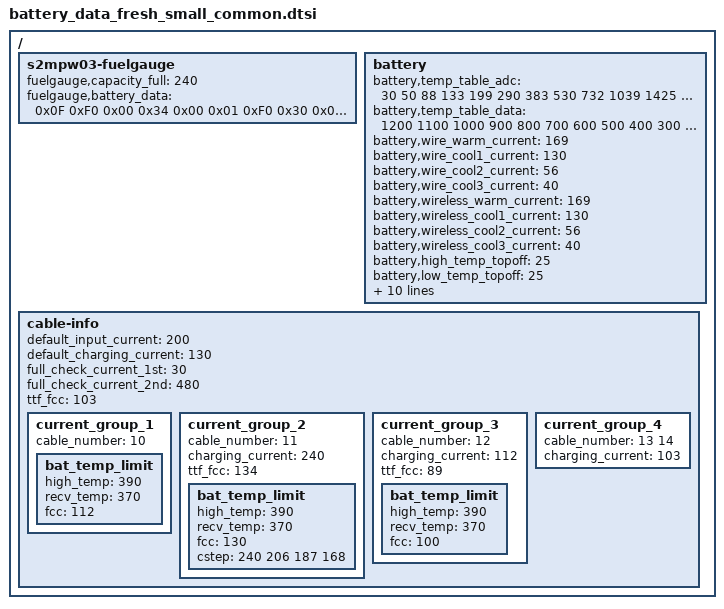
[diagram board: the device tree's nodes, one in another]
/*
 * SAMSUNG EXYNOS5515 board device tree source
 *
 * Copyright (c) 2021 Samsung Electronics Co., Ltd.
 *		http://www.samsung.com
 *
 * This program is free software; you can redistribute it and/or modify
 * it under the terms of the GNU General Public License version 2 as
 * published by the Free Software Foundation.
 */

#include "battery_data_fresh_common.dtsi"

/ {
	fragment@battery {
		target-path = "/";
		__overlay__ {
			s2mpw03-fuelgauge {
				fuelgauge,capacity_full = <240>;

				fuelgauge,battery_data = /bits/ 8 <
					/* 4.42V */
					/* table1 */
					0x0F 0xF0 0x00 0x34 0x00
					/* table2 */
					0x01 0xF0
					/* model_param1 */
					0x30 0x0B 0xD6 0x0A 0x7C 0x0A 0x31 0x0A 0xBB 0x09
					0x48 0x09 0xDA 0x08 0x73 0x08 0x13 0x08 0xA7 0x07
					0x44 0x07 0xFE 0x06 0xC9 0x06 0x9D 0x06 0x78 0x06
					0x54 0x06 0x25 0x06 0xF6 0x05 0xBC 0x05 0x94 0x05
					0x23 0x05 0xCB 0x02 0x66 0x08 0x00 0x08 0x9A 0x07
					0x33 0x07 0xCD 0x06 0x66 0x06 0x00 0x06 0x9A 0x05
					0x33 0x05 0xCD 0x04 0x66 0x04 0x00 0x04 0x9A 0x03
					0x33 0x03 0xCD 0x02 0x66 0x02 0x00 0x02 0x9A 0x01
					0x33 0x01 0xCD 0x00 0x66 0x00 0x00 0x00
					/* model_param2 */
					0xE5 0xFF 0xFF 0xED 0xED 0xE9 0xE4 0xE1 0xDC 0xD9
					0xD7 0xD5 0xDA 0xDC 0xFF 0xFF 0xFF 0xFF 0xF1 0xFE
					0xEA 0xE3

					/* 4.4V */
					/* table1 */
					0x0F 0xE9 0x00 0x34 0x00
					/* table2 */
					0x01 0xF0
					/* model_param1 */
					0x3C 0x0B 0xD0 0x0A 0x64 0x0A 0x1B 0x0A 0xA6 0x09
					0x34 0x09 0xC7 0x08 0x62 0x08 0x04 0x08 0x95 0x07
					0x35 0x07 0xF5 0x06 0xC2 0x06 0x97 0x06 0x73 0x06
					0x4F 0x06 0x1F 0x06 0xF0 0x05 0xB5 0x05 0x92 0x05
					0x0F 0x05 0xCC 0x02 0x66 0x08 0x00 0x08 0x9A 0x07
					0x33 0x07 0xCD 0x06 0x66 0x06 0x00 0x06 0x9A 0x05
					0x33 0x05 0xCD 0x04 0x66 0x04 0x00 0x04 0x9A 0x03
					0x33 0x03 0xCD 0x02 0x66 0x02 0x00 0x02 0x9A 0x01
					0x33 0x01 0xCD 0x00 0x66 0x00 0x00 0x00
					/* model_param2 */
					0xE5 0xFF 0xFF 0xED 0xED 0xE9 0xE4 0xE1 0xDC 0xD9
					0xD7 0xD5 0xDA 0xDC 0xFF 0xFF 0xFF 0xFF 0xF1 0xFE
					0xEA 0xE3

					/* 4.38V */
					/* table1 */
					0x0F 0xE5 0x00 0x34 0x00
					/* table2 */
					0x01 0xF0
					/* model_param1 */
					0x13 0x0B 0xA7 0x0A 0x3B 0x0A 0xF3 0x09 0x81 0x09
					0x13 0x09 0xAA 0x08 0x49 0x08 0xE8 0x07 0x7F 0x07
					0x26 0x07 0xEA 0x06 0xBA 0x06 0x91 0x06 0x6F 0x06
					0x4B 0x06 0x1A 0x06 0xED 0x05 0xB1 0x05 0x91 0x05
					0x0C 0x05 0xCD 0x02 0x66 0x08 0x00 0x08 0x9A 0x07
					0x33 0x07 0xCD 0x06 0x66 0x06 0x00 0x06 0x9A 0x05
					0x33 0x05 0xCD 0x04 0x66 0x04 0x00 0x04 0x9A 0x03
					0x33 0x03 0xCD 0x02 0x66 0x02 0x00 0x02 0x9A 0x01
					0x33 0x01 0xCD 0x00 0x66 0x00 0x00 0x00
					/* model_param2 */
					0xE5 0xFF 0xFF 0xED 0xED 0xE9 0xE4 0xE1 0xDC 0xD9
					0xD7 0xD5 0xDA 0xDC 0xFF 0xFF 0xFF 0xFF 0xF1 0xFE
					0xEA 0xE3

					/* 4.36V */
					/* table1 */
					0x0F 0xE0 0x00 0x34 0x00
					/* table2 */
					0x01 0xF0
					/* model_param1 */
					0xE6 0x0B 0x79 0x0A 0x0C 0x0A 0xC5 0x09 0x56 0x09
					0xED 0x08 0x89 0x08 0x2C 0x08 0xC9 0x07 0x66 0x07
					0x17 0x07 0xDF 0x06 0xB2 0x06 0x8B 0x06 0x69 0x06
					0x45 0x06 0x14 0x06 0xE9 0x05 0xAD 0x05 0x90 0x05
					0x08 0x05 0xCD 0x02 0x66 0x08 0x00 0x08 0x9A 0x07
					0x33 0x07 0xCD 0x06 0x66 0x06 0x00 0x06 0x9A 0x05
					0x33 0x05 0xCD 0x04 0x66 0x04 0x00 0x04 0x9A 0x03
					0x33 0x03 0xCD 0x02 0x66 0x02 0x00 0x02 0x9A 0x01
					0x33 0x01 0xCD 0x00 0x66 0x00 0x00 0x00
					/* model_param2 */
					0xE5 0xFF 0xFF 0xED 0xED 0xE9 0xE4 0xE1 0xDC 0xD9
					0xD7 0xD5 0xDA 0xDC 0xFF 0xFF 0xFF 0xFF 0xF1 0xFE
					0xEA 0xE3

					/* 4.31V */
					/* table1 */
					0x0F 0xD5 0x00 0x34 0x00
					/* table2 */
					0x01 0xF0
					/* model_param1 */
					0x7E 0x0A 0x14 0x0A 0xA9 0x09 0x69 0x09 0x03 0x09
					0xA3 0x08 0x48 0x08 0xEE 0x07 0x8A 0x07 0x33 0x07
					0xF9 0x06 0xC9 0x06 0xA1 0x06 0x7F 0x06 0x5E 0x06
					0x38 0x06 0x0A 0x06 0xE0 0x05 0xA4 0x05 0x8E 0x05
					0x00 0x05 0xCD 0x02 0x66 0x08 0x00 0x08 0x9A 0x07
					0x33 0x07 0xCD 0x06 0x66 0x06 0x00 0x06 0x9A 0x05
					0x33 0x05 0xCD 0x04 0x66 0x04 0x00 0x04 0x9A 0x03
					0x33 0x03 0xCD 0x02 0x66 0x02 0x00 0x02 0x9A 0x01
					0x33 0x01 0xCD 0x00 0x66 0x00 0x00 0x00
					/* model_param2 */
					0xE5 0xFF 0xFF 0xED 0xED 0xE9 0xE4 0xE1 0xDC 0xD9
					0xD7 0xD5 0xDA 0xDC 0xFF 0xFF 0xFF 0xFF 0xF1 0xFE
					0xEA 0xE3
				>;
			};

			battery {
				battery,temp_table_adc = <
							30 50 88 133 199 290 383 530 732 1039
							1425 1871 2365 2853 3324
							>;
				battery,temp_table_data = <
							1200 1100 1000 900 800 700 600 500 400 300
							200 100 0 (-100) (-200)
							>;

				battery,wire_warm_current = <169>;	/* 0.36C */
				battery,wire_cool1_current = <130>;	/* Not used */
				battery,wire_cool2_current = <56>;	/* 0.24C */
				battery,wire_cool3_current = <40>;	/* 0.16C */

				battery,wireless_warm_current = <169>;	/* 0.24C */
				battery,wireless_cool1_current = <130>;	/* Not used */
				battery,wireless_cool2_current = <56>;	/* 0.24C */
				battery,wireless_cool3_current = <40>;	/* 0.16C */

				battery,high_temp_topoff = <25>;	/* 0.05C */
				battery,low_temp_topoff = <25>;		/* 0.05C */

				battery,standard_curr = <169>;
				battery,cc2_charge_current = <169>;
				battery,tct_low_current = <103>;
				battery,store_wpc_current = <75>;
				battery,age_data_cc_cv_threshold = <4150 4150 4150 4150 4150>;

				battery,battery_full_capacity = <240>;
				battery,ttf_capacity = <240>;
				battery,cv_data = <
					182	860	1147
					172	870	1086
					160	880	1026
					146	890	966
					135	900	905
					127	910	845
					118	920	785
					113	930	725
					101	940	604
					96	950	544
					86	960	422
					83	970	362
					74	980	241
					67	990	121
					59	1000	0
					>;
			};

			/* sec_battery_cable
			 *   0	UNKNOWN,
			 *   1	NONE,
			 *   2	TA,
			 *   3	USB,
			 *   4	UARTOFF,
			 *   5	RESERVED,
			 *   6	RESERVED,
			 *   7	RESERVED,
			 *   8	RESERVED,
			 *   9	RESERVED,
			 *  10	WRL,
			 *  11	INBOX_WRL,
			 *  12	D2D_WRL,
			 *  13	INCOMP_WRL,
			 *  14	ERR_WRL,
			 */
			cable-info {
				default_input_current = <200>;
				default_charging_current = <130>;
				full_check_current_1st = <30>;
				full_check_current_2nd = <480>;	/* time: 8min */
				ttf_fcc = <103>;

				current_group_1 {
					cable_number = <10>;

					bat_temp_limit {
						high_temp = <390>;
						recv_temp = <370>;
						fcc = <112>;
					};
				};

				current_group_2 {
					cable_number = <11>;
					charging_current = <240>;	/* 1C */
					ttf_fcc = <134>;

					bat_temp_limit {
						high_temp = <390>;
						recv_temp = <370>;
						fcc = <130>;
						cstep = <240 206 187 168>; /* 1C 0.9C 0.8C 0.7C */
					};
				};

				current_group_3 {
					cable_number = <12>;
					charging_current = <112>;
					ttf_fcc = <89>;

					bat_temp_limit {
						high_temp = <390>;
						recv_temp = <370>;
						fcc = <100>;
					};
				};

				current_group_4 {
					cable_number = <13 14>;
					charging_current = <103>;
				};
			};
		};
	};
};
